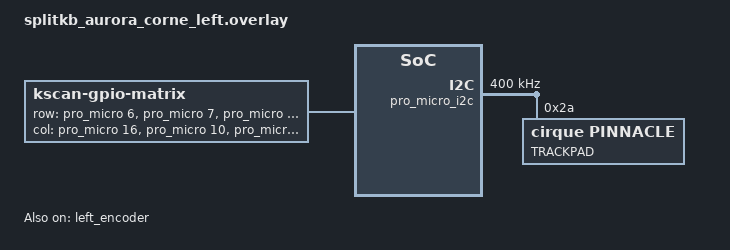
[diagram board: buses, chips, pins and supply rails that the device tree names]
/*
 * Copyright (c) 2022 The ZMK Contributors
 *
 * SPDX-License-Identifier: MIT
 */

#include "splitkb_aurora_corne.dtsi"

/ {
    chosen {
        zmk,kscan = &kscan;
    };

    kscan: kscan {
        compatible = "zmk,kscan-gpio-matrix";

        label = "KSCAN";
        diode-direction = "col2row";

        row-gpios
            = <&pro_micro 6 (GPIO_PULL_DOWN | GPIO_ACTIVE_HIGH)>
            , <&pro_micro 7 (GPIO_PULL_DOWN | GPIO_ACTIVE_HIGH)>
            , <&pro_micro 8 (GPIO_PULL_DOWN | GPIO_ACTIVE_HIGH)>
            , <&pro_micro 9 (GPIO_PULL_DOWN | GPIO_ACTIVE_HIGH)>
            ;

        col-gpios
            = <&pro_micro 16 GPIO_ACTIVE_HIGH>
            , <&pro_micro 10 GPIO_ACTIVE_HIGH>
            , <&pro_micro 14 GPIO_ACTIVE_HIGH>
            , <&pro_micro 15 GPIO_ACTIVE_HIGH>
            , <&pro_micro 18 GPIO_ACTIVE_HIGH>
            , <&pro_micro 19 GPIO_ACTIVE_HIGH>
            ;
    };

};

&left_encoder {
    status = "okay";
};

&pro_micro_i2c {
    status = "okay";
    clock-frequency = <400000>;

    trackpad:trackpad@2a {
        compatible = "cirque,pinnacle";
        status = "okay";
        label = "TRACKPAD";
        reg = <0x2A>;
        rotate-90;
        sleep;
        /* no-taps; */
    };

};


